# RX64M_TEMPS_Pilot register map
File version: 1.0
RX64M_TEMPS_Pilot peripheral registers generated from iodefine.h (pilot).
Registers are 8-bit, read-write, reset 0x0 unless marked. A register's access mark holds for its fields unless they carry their own. Offsets are from the block's base; lines under a group give offsets from that group; [hi:lo] are bit positions; {n}, {i} and the like mark numbered series; 'fields as' and 'values as' point back to an identical list; <NAME> marks a mode.

## Memory map
0x0008C500 TEMPS size 0x1

## TEMPS
Base 0x0008C500
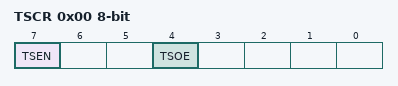
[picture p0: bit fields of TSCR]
0x00 TSCR
  [7] TSEN, [4] TSOE
